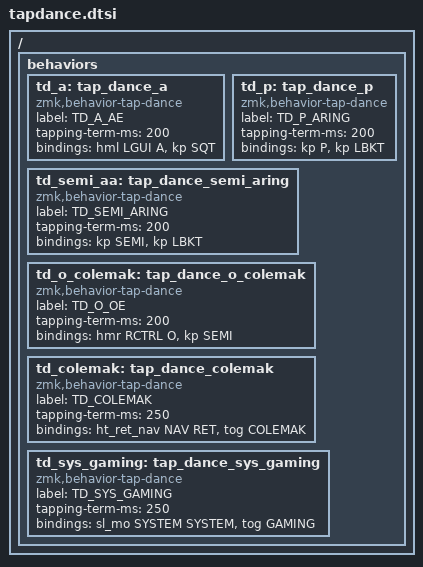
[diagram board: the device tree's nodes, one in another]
/ {
    behaviors {

        td_a: tap_dance_a {
            compatible = "zmk,behavior-tap-dance";
            label = "TD_A_AE";             // tap → A (GUI when held) | double-tap → ä/Ä
            #binding-cells = <0>;
            tapping-term-ms = <200>;
            // SE layout: HID APOS (0x34) = ä/Ä. RA(Q) was wrong — that gives @ on SE.
            bindings = <&hml LGUI A>, <&kp SQT>;
        };

        td_p: tap_dance_p {
            compatible = "zmk,behavior-tap-dance";
            label = "TD_P_ARING";          // tap → P | double-tap → å/Å (A-ring)
            #binding-cells = <0>;
            tapping-term-ms = <200>;
            // SE layout: HID LBKT (0x2F) = å/Å. RA(A) was wrong — that is not Å on SE.
            bindings = <&kp P>, <&kp LBKT>;
        };

        td_semi_aa: tap_dance_semi_aring {
            compatible = "zmk,behavior-tap-dance";
            label = "TD_SEMI_ARING";       // tap → ; | double-tap → å/Å  (Colemak top-right)
            #binding-cells = <0>;
            tapping-term-ms = <200>;
            // SE layout: HID LBKT (0x2F) = å/Å.
            bindings = <&kp SEMI>, <&kp LBKT>;
        };

        td_o_colemak: tap_dance_o_colemak {
            compatible = "zmk,behavior-tap-dance";
            label = "TD_O_OE";             // tap → O (RCTRL when held) | double-tap → ö/Ö  (Colemak home-right)
            #binding-cells = <0>;
            tapping-term-ms = <200>;
            // SE layout: HID SEMI (0x33) = ö/Ö. RA(O) was wrong — that is not Ö on SE.
            bindings = <&hmr RCTRL O>, <&kp SEMI>;
        };

        td_colemak: tap_dance_colemak {
            compatible = "zmk,behavior-tap-dance";
            label = "TD_COLEMAK";
            #binding-cells = <0>;
            tapping-term-ms = <250>;
            // Tap/hold = Enter / momentary NAV; double-tap = toggle Colemak DH
            bindings = <&ht_ret_nav NAV RET>, <&tog COLEMAK>;
        };

        // Replaces the old `&mo_tog SYSTEM SYSTEM` on the left SYS thumb.
        // Single-tap → momentary SYSTEM (media, BT controls, etc.)
        // Double-tap → toggle GAMING layer on/off
        //
        // Why a tap-dance and not `&mo_tog`: `mo_tog` couples the hold target
        // and the double-tap target. We need momentary SYSTEM on tap-hold and
        // a DIFFERENT layer (GAMING) on double-tap.
        td_sys_gaming: tap_dance_sys_gaming {
            compatible = "zmk,behavior-tap-dance";
            label = "TD_SYS_GAMING";
            #binding-cells = <0>;
            tapping-term-ms = <250>;
            // Tap  → sticky SYSTEM (&sl): press+release SYS, then press a key on SYSTEM layer
            // Hold → momentary SYSTEM (&mo): holds layer active while thumb is down
            // Double-tap → toggle GAMING on/off
            bindings = <&sl_mo SYSTEM SYSTEM>, <&tog GAMING>;
        };

    };
};
